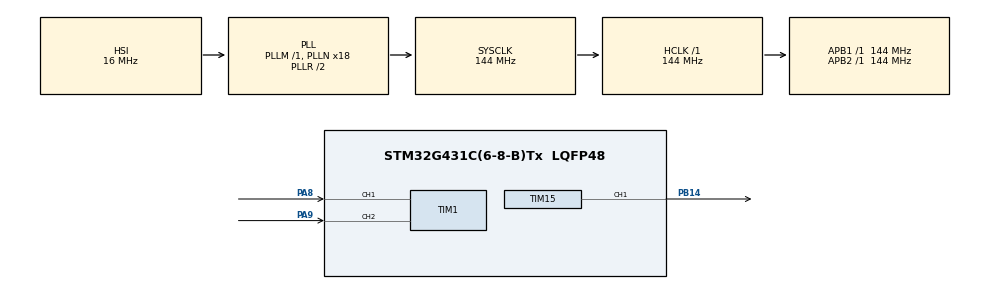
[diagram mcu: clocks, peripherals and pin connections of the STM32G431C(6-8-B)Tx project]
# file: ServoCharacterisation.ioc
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FREERTOS.Tasks01=sampleEncoder,24,128,sampleEncoderFn,Default,NULL,Dynamic,NULL,NULL;servoCmd,24,128,servoCmdFn,Default,NULL,Dynamic,NULL,NULL;logData,24,128,logDataFn,Default,NULL,Dynamic,NULL,NULL
FREERTOS.configENABLE_FPU=1
FREERTOS.configUSE_NEWLIB_REENTRANT=1
Mcu.Family=STM32G4
Mcu.Name=STM32G431C(6-8-B)Tx
Mcu.Package=LQFP48
NVIC.PriorityGroup=NVIC_PRIORITYGROUP_4
NVIC.TIM6_DAC_IRQn=true\:15\:0\:false\:false\:true\:false\:false\:true\:true
NVIC.TimeBase=TIM6_DAC_IRQn
NVIC.TimeBaseIP=TIM6
PA13.Mode=Trace_Asynchronous_SW
PA13.Signal=SYS_JTMS-SWDIO
PA14.Mode=Trace_Asynchronous_SW
PA14.Signal=SYS_JTCK-SWCLK
PA8.Signal=S_TIM1_CH1
PA9.Signal=S_TIM1_CH2
PB14.Signal=S_TIM15_CH1
PB3.Mode=Trace_Asynchronous_SW
PB3.Signal=SYS_JTDO-SWO
ProjectManager.HeapSize=0x200
ProjectManager.StackSize=0x400
ProjectManager.TargetToolchain=STM32CubeIDE
RCC.ADC12Freq_Value=144000000
RCC.AHBFreq_Value=144000000
RCC.APB1Freq_Value=144000000
RCC.APB1TimFreq_Value=144000000
RCC.APB2Freq_Value=144000000
RCC.APB2TimFreq_Value=144000000
RCC.CortexFreq_Value=144000000
RCC.EXTERNAL_CLOCK_VALUE=12288000
RCC.HCLKFreq_Value=144000000
RCC.HSE_VALUE=8000000
RCC.HSI48_VALUE=48000000
RCC.HSI_VALUE=16000000
RCC.LSE_VALUE=32768
RCC.PLLN=18
RCC.SYSCLKFreq_VALUE=144000000
RCC.SYSCLKSource=RCC_SYSCLKSOURCE_PLLCLK
RCC.USBFreq_Value=144000000
RCC.VCOOutputFreq_Value=288000000
SH.S_TIM15_CH1.0=TIM15_CH1,PWM Generation1 CH1
SH.S_TIM1_CH1.0=TIM1_CH1,Encoder_Interface
SH.S_TIM1_CH2.0=TIM1_CH2,Encoder_Interface
TIM1.EncoderMode=TIM_ENCODERMODE_TI12
TIM1.IC1Filter=15
TIM1.IC2Filter=15
TIM15.Channel-PWM\ Generation1\ CH1=TIM_CHANNEL_1
TIM15.PeriodNoDither=65535
TIM15.Prescaler=144-1
TIM2.Prescaler=144-1
TIM8.Prescaler=144-1
VP_FREERTOS_VS_CMSIS_V2.Mode=CMSIS_V2
VP_SYS_VS_DBSignals.Mode=DisableDeadBatterySignals
VP_SYS_VS_tim6.Mode=TIM6
VP_TIM15_VS_ClockSourceINT.Mode=Internal
VP_TIM2_VS_ClockSourceINT.Mode=Internal
VP_TIM8_VS_ClockSourceINT.Mode=Internal
board=custom

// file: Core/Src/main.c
/* USER CODE BEGIN Header */
/**
  ******************************************************************************
  * @file           : main.c
  * @brief          : Main program body
  ******************************************************************************
  * @attention
  *
  * Copyright (c) 2025 STMicroelectronics.
  * All rights reserved.
  *
  * This software is licensed under terms that can be found in the LICENSE file
  * in the root directory of this software component.
  * If no LICENSE file comes with this software, it is provided AS-IS.
  *
  ******************************************************************************
  */
/* USER CODE END Header */
#include "main.h"
#include "cmsis_os.h"

/* USER CODE BEGIN Includes */
#include "encoder.h"
#include "ServoControl.h"
/* USER CODE END Includes */

/* USER CODE BEGIN PD */
#define ENC_SAMPLE_TIME_MS 10
/* USER CODE END PD */

TIM_HandleTypeDef htim1;
TIM_HandleTypeDef htim2;
TIM_HandleTypeDef htim8;
TIM_HandleTypeDef htim15;

/* Definitions for sampleEncoder */
osThreadId_t sampleEncoderHandle;
const osThreadAttr_t sampleEncoder_attributes = {
  .name = "sampleEncoder",
  .priority = (osPriority_t) osPriorityNormal,
  .stack_size = 128 * 4
};
/* Definitions for servoCmd */
osThreadId_t servoCmdHandle;
const osThreadAttr_t servoCmd_attributes = {
  .name = "servoCmd",
  .priority = (osPriority_t) osPriorityNormal,
  .stack_size = 128 * 4
};
/* Definitions for logData */
osThreadId_t logDataHandle;
const osThreadAttr_t logData_attributes = {
  .name = "logData",
  .priority = (osPriority_t) osPriorityNormal,
  .stack_size = 128 * 4
};
/* USER CODE BEGIN PV */
TIM_HandleTypeDef* EncoderTimer = &htim1;
TIM_HandleTypeDef* ServoTimer = &htim15;
TIM_HandleTypeDef* MicrosTimer = &htim2;
TIM_HandleTypeDef* MillisTimer = &htim8;

float encoderPulses = 0;
float position = 0.0f;

/* USER CODE END PV */

void SystemClock_Config(void);
static void MX_GPIO_Init(void);
static void MX_TIM1_Init(void);
static void MX_TIM15_Init(void);
static void MX_TIM2_Init(void);
static void MX_TIM8_Init(void);
void sampleEncoderFn(void *argument);
void servoCmdFn(void *argument);
void logDataFn(void *argument);

/* USER CODE BEGIN PFP */
uint32_t micros(void) {
	return MicrosTimer->Instance->CNT;
}

uint32_t millis(void) {
	return MillisTimer->Instance->CNT;
}
/* USER CODE END PFP */

int main(void)
{

  /* MCU Configuration--------------------------------------------------------*/

  /* Reset of all peripherals, Initializes the Flash interface and the Systick. */
  HAL_Init();

  /* Configure the system clock */
  SystemClock_Config();

  /* Initialize all configured peripherals */
  MX_GPIO_Init();
  MX_TIM1_Init();
  MX_TIM15_Init();
  MX_TIM2_Init();
  MX_TIM8_Init();

  /* Init scheduler */
  osKernelInitialize();

  /* Create the thread(s) */
  /* creation of sampleEncoder */
  sampleEncoderHandle = osThreadNew(sampleEncoderFn, NULL, &sampleEncoder_attributes);

  /* creation of servoCmd */
  servoCmdHandle = osThreadNew(servoCmdFn, NULL, &servoCmd_attributes);

  /* creation of logData */
  logDataHandle = osThreadNew(logDataFn, NULL, &logData_attributes);

  /* USER CODE BEGIN RTOS_EVENTS */
  /* add events, ... */
  HAL_TIM_Base_Start(MicrosTimer);
  HAL_TIM_Base_Start(MillisTimer);
  /* USER CODE END RTOS_EVENTS */

  /* Start scheduler */
  osKernelStart();

  /* We should never get here as control is now taken by the scheduler */

  /* Infinite loop */
  while (1)
  {

  }
}

void SystemClock_Config(void)
{
  RCC_OscInitTypeDef RCC_OscInitStruct = {0};
  RCC_ClkInitTypeDef RCC_ClkInitStruct = {0};

  /** Configure the main internal regulator output voltage
  */
  HAL_PWREx_ControlVoltageScaling(PWR_REGULATOR_VOLTAGE_SCALE1);

  /** Initializes the RCC Oscillators according to the specified parameters
  * in the RCC_OscInitTypeDef structure.
  */
  RCC_OscInitStruct.OscillatorType = RCC_OSCILLATORTYPE_HSI;
  RCC_OscInitStruct.HSIState = RCC_HSI_ON;
  RCC_OscInitStruct.HSICalibrationValue = RCC_HSICALIBRATION_DEFAULT;
  RCC_OscInitStruct.PLL.PLLState = RCC_PLL_ON;
  RCC_OscInitStruct.PLL.PLLSource = RCC_PLLSOURCE_HSI;
  RCC_OscInitStruct.PLL.PLLM = RCC_PLLM_DIV1;
  RCC_OscInitStruct.PLL.PLLN = 18;
  RCC_OscInitStruct.PLL.PLLP = RCC_PLLP_DIV2;
  RCC_OscInitStruct.PLL.PLLQ = RCC_PLLQ_DIV2;
  RCC_OscInitStruct.PLL.PLLR = RCC_PLLR_DIV2;
  if (HAL_RCC_OscConfig(&RCC_OscInitStruct) != HAL_OK)
  {
    Error_Handler();
  }

  /** Initializes the CPU, AHB and APB buses clocks
  */
  RCC_ClkInitStruct.ClockType = RCC_CLOCKTYPE_HCLK|RCC_CLOCKTYPE_SYSCLK
                              |RCC_CLOCKTYPE_PCLK1|RCC_CLOCKTYPE_PCLK2;
  RCC_ClkInitStruct.SYSCLKSource = RCC_SYSCLKSOURCE_PLLCLK;
  RCC_ClkInitStruct.AHBCLKDivider = RCC_SYSCLK_DIV1;
  RCC_ClkInitStruct.APB1CLKDivider = RCC_HCLK_DIV1;
  RCC_ClkInitStruct.APB2CLKDivider = RCC_HCLK_DIV1;

  if (HAL_RCC_ClockConfig(&RCC_ClkInitStruct, FLASH_LATENCY_4) != HAL_OK)
  {
    Error_Handler();
  }
}

static void MX_TIM1_Init(void)
{

  TIM_Encoder_InitTypeDef sConfig = {0};
  TIM_MasterConfigTypeDef sMasterConfig = {0};

  htim1.Instance = TIM1;
  htim1.Init.Prescaler = 0;
  htim1.Init.CounterMode = TIM_COUNTERMODE_UP;
  htim1.Init.Period = 65535;
  htim1.Init.ClockDivision = TIM_CLOCKDIVISION_DIV1;
  htim1.Init.RepetitionCounter = 0;
  htim1.Init.AutoReloadPreload = TIM_AUTORELOAD_PRELOAD_DISABLE;
  sConfig.EncoderMode = TIM_ENCODERMODE_TI12;
  sConfig.IC1Polarity = TIM_ICPOLARITY_RISING;
  sConfig.IC1Selection = TIM_ICSELECTION_DIRECTTI;
  sConfig.IC1Prescaler = TIM_ICPSC_DIV1;
  sConfig.IC1Filter = 15;
  sConfig.IC2Polarity = TIM_ICPOLARITY_RISING;
  sConfig.IC2Selection = TIM_ICSELECTION_DIRECTTI;
  sConfig.IC2Prescaler = TIM_ICPSC_DIV1;
  sConfig.IC2Filter = 15;
  if (HAL_TIM_Encoder_Init(&htim1, &sConfig) != HAL_OK)
  {
    Error_Handler();
  }
  sMasterConfig.MasterOutputTrigger = TIM_TRGO_RESET;
  sMasterConfig.MasterOutputTrigger2 = TIM_TRGO2_RESET;
  sMasterConfig.MasterSlaveMode = TIM_MASTERSLAVEMODE_DISABLE;
  if (HAL_TIMEx_MasterConfigSynchronization(&htim1, &sMasterConfig) != HAL_OK)
  {
    Error_Handler();
  }

}

static void MX_TIM2_Init(void)
{

  TIM_ClockConfigTypeDef sClockSourceConfig = {0};
  TIM_MasterConfigTypeDef sMasterConfig = {0};

  htim2.Instance = TIM2;
  htim2.Init.Prescaler = 144-1;
  htim2.Init.CounterMode = TIM_COUNTERMODE_UP;
  htim2.Init.Period = 4294967295;
  htim2.Init.ClockDivision = TIM_CLOCKDIVISION_DIV1;
  htim2.Init.AutoReloadPreload = TIM_AUTORELOAD_PRELOAD_DISABLE;
  if (HAL_TIM_Base_Init(&htim2) != HAL_OK)
  {
    Error_Handler();
  }
  sClockSourceConfig.ClockSource = TIM_CLOCKSOURCE_INTERNAL;
  if (HAL_TIM_ConfigClockSource(&htim2, &sClockSourceConfig) != HAL_OK)
  {
    Error_Handler();
  }
  sMasterConfig.MasterOutputTrigger = TIM_TRGO_RESET;
  sMasterConfig.MasterSlaveMode = TIM_MASTERSLAVEMODE_DISABLE;
  if (HAL_TIMEx_MasterConfigSynchronization(&htim2, &sMasterConfig) != HAL_OK)
  {
    Error_Handler();
  }

}

static void MX_TIM8_Init(void)
{

  TIM_ClockConfigTypeDef sClockSourceConfig = {0};
  TIM_MasterConfigTypeDef sMasterConfig = {0};

  htim8.Instance = TIM8;
  htim8.Init.Prescaler = 144-1;
  htim8.Init.CounterMode = TIM_COUNTERMODE_UP;
  htim8.Init.Period = 65535;
  htim8.Init.ClockDivision = TIM_CLOCKDIVISION_DIV1;
  htim8.Init.RepetitionCounter = 0;
  htim8.Init.AutoReloadPreload = TIM_AUTORELOAD_PRELOAD_DISABLE;
  if (HAL_TIM_Base_Init(&htim8) != HAL_OK)
  {
    Error_Handler();
  }
  sClockSourceConfig.ClockSource = TIM_CLOCKSOURCE_INTERNAL;
  if (HAL_TIM_ConfigClockSource(&htim8, &sClockSourceConfig) != HAL_OK)
  {
    Error_Handler();
  }
  sMasterConfig.MasterOutputTrigger = TIM_TRGO_RESET;
  sMasterConfig.MasterOutputTrigger2 = TIM_TRGO2_RESET;
  sMasterConfig.MasterSlaveMode = TIM_MASTERSLAVEMODE_DISABLE;
  if (HAL_TIMEx_MasterConfigSynchronization(&htim8, &sMasterConfig) != HAL_OK)
  {
    Error_Handler();
  }

}

static void MX_TIM15_Init(void)
{

  TIM_ClockConfigTypeDef sClockSourceConfig = {0};
  TIM_MasterConfigTypeDef sMasterConfig = {0};
  TIM_OC_InitTypeDef sConfigOC = {0};
  TIM_BreakDeadTimeConfigTypeDef sBreakDeadTimeConfig = {0};

  htim15.Instance = TIM15;
  htim15.Init.Prescaler = 144-1;
  htim15.Init.CounterMode = TIM_COUNTERMODE_UP;
  htim15.Init.Period = 65535;
  htim15.Init.ClockDivision = TIM_CLOCKDIVISION_DIV1;
  htim15.Init.RepetitionCounter = 0;
  htim15.Init.AutoReloadPreload = TIM_AUTORELOAD_PRELOAD_DISABLE;
  if (HAL_TIM_Base_Init(&htim15) != HAL_OK)
  {
    Error_Handler();
  }
  sClockSourceConfig.ClockSource = TIM_CLOCKSOURCE_INTERNAL;
  if (HAL_TIM_ConfigClockSource(&htim15, &sClockSourceConfig) != HAL_OK)
  {
    Error_Handler();
  }
  if (HAL_TIM_PWM_Init(&htim15) != HAL_OK)
  {
    Error_Handler();
  }
  sMasterConfig.MasterOutputTrigger = TIM_TRGO_RESET;
  sMasterConfig.MasterSlaveMode = TIM_MASTERSLAVEMODE_DISABLE;
  if (HAL_TIMEx_MasterConfigSynchronization(&htim15, &sMasterConfig) != HAL_OK)
  {
    Error_Handler();
  }
  sConfigOC.OCMode = TIM_OCMODE_PWM1;
  sConfigOC.Pulse = 0;
  sConfigOC.OCPolarity = TIM_OCPOLARITY_HIGH;
  sConfigOC.OCNPolarity = TIM_OCNPOLARITY_HIGH;
  sConfigOC.OCFastMode = TIM_OCFAST_DISABLE;
  sConfigOC.OCIdleState = TIM_OCIDLESTATE_RESET;
  sConfigOC.OCNIdleState = TIM_OCNIDLESTATE_RESET;
  if (HAL_TIM_PWM_ConfigChannel(&htim15, &sConfigOC, TIM_CHANNEL_1) != HAL_OK)
  {
    Error_Handler();
  }
  sBreakDeadTimeConfig.OffStateRunMode = TIM_OSSR_DISABLE;
  sBreakDeadTimeConfig.OffStateIDLEMode = TIM_OSSI_DISABLE;
  sBreakDeadTimeConfig.LockLevel = TIM_LOCKLEVEL_OFF;
  sBreakDeadTimeConfig.DeadTime = 0;
  sBreakDeadTimeConfig.BreakState = TIM_BREAK_DISABLE;
  sBreakDeadTimeConfig.BreakPolarity = TIM_BREAKPOLARITY_HIGH;
  sBreakDeadTimeConfig.BreakFilter = 0;
  sBreakDeadTimeConfig.AutomaticOutput = TIM_AUTOMATICOUTPUT_DISABLE;
  if (HAL_TIMEx_ConfigBreakDeadTime(&htim15, &sBreakDeadTimeConfig) != HAL_OK)
  {
    Error_Handler();
  }
  HAL_TIM_MspPostInit(&htim15);

}

static void MX_GPIO_Init(void)
{

  /* GPIO Ports Clock Enable */
  __HAL_RCC_GPIOB_CLK_ENABLE();
  __HAL_RCC_GPIOA_CLK_ENABLE();

}

void sampleEncoderFn(void *argument)
{
  /* USER CODE BEGIN 5 */
	encoderHandle_t eHandlePtr = {
				.encTimer = EncoderTimer,
				.pulseVel = 0.0f,
				.totalPulses = 0.
		};

	encoderStart(&eHandlePtr, 400, 1);

	uint32_t previousTime = millis();
	uint32_t currentTime = millis();
	float dt = -1;
	/* Infinite loop */
	for(;;)
	{
	  // Calculate dt for this iteration
	  dt = currentTime - previousTime;

	  if (dt > ENC_SAMPLE_TIME_MS) {
		  // Read from encoder
		  sampleEncoder(&eHandlePtr, dt/1E3);

		  encoderPulses = (float) eHandlePtr.totalPulses;
		  // Update the current position
//		  discStatus.currentPosition = eHandlePtr.totalPulses * ENC_TICKS_TO_DEG;

	//		  // Add it to the queue - message priority ignored
	//		  osMessageQueuePut(timEncoderHandle, &currentEncoder, 0, osWaitForever);

		  previousTime = millis();
	  }

	  currentTime = millis();
	  osDelay(1);
	}
  /* USER CODE END 5 */
}

void servoCmdFn(void *argument)
{
  /* USER CODE BEGIN servoCmdFn */
	ServoHandle_t servo = {
			.htim = ServoTimer,
			.currentPos = 0,
			.freqPWM = 300
	};

	servo_start(&servo);

  /* Infinite loop */
  for(;;)
  {
	  new_servo_move(&servo, position);
	  osDelay(500);
	  position += 0.05;
	  if (position > 1) {
		  position = 0;
	  }

//	  position += shouldCountUp*0.05;
//
//	  if (position > 1 && shouldCountUp == 1) {
//		  shouldCountUp = -1;
//	  }
//	  else if (position < 0 && shouldCountUp == -1) {
//		  shouldCountUp = 1;
//	  }
  }
  /* USER CODE END servoCmdFn */
}

void logDataFn(void *argument)
{
  for(;;)
  {
    osDelay(1);
  }
}

void HAL_TIM_PeriodElapsedCallback(TIM_HandleTypeDef *htim)
{
  if (htim->Instance == TIM6) {
    HAL_IncTick();
  }
}

void Error_Handler(void)
{
  __disable_irq();
  while (1)
  {
  }
}
